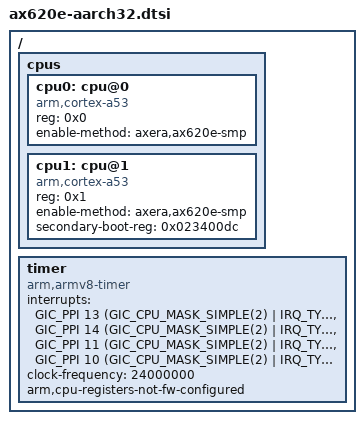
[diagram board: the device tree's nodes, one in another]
// SPDX-License-Identifier: GPL-2.0-or-later
/*
 * Copyright (c) 2026, GembaHive, Inc.
 */
/*
 * The AX620E's CPUs and timer under a 32-bit kernel. A board includes this
 * before its chip file, so these nodes come first in the DTB.
 */

#include <dt-bindings/interrupt-controller/arm-gic.h>

/ {
	cpus {
		#address-cells = <1>;
		#size-cells = <0>;

		cpu0: cpu@0 {
			device_type = "cpu";
			compatible = "arm,cortex-a53";
			reg = <0x0>;
			enable-method = "axera,ax620e-smp";
		};

		cpu1: cpu@1 {
			device_type = "cpu";
			compatible = "arm,cortex-a53";
			reg = <0x1>;
			enable-method = "axera,ax620e-smp";
			secondary-boot-reg = <0x023400dc>;
		};
	};

	/*
	 * A53 timer PPIs are active-low; no firmware sets CNTFRQ (the 24 MHz
	 * crystal) or CNTVOFF.
	 */
	timer {
		compatible = "arm,armv8-timer";
		interrupts = <GIC_PPI 13 (GIC_CPU_MASK_SIMPLE(2) | IRQ_TYPE_LEVEL_LOW)>,
			     <GIC_PPI 14 (GIC_CPU_MASK_SIMPLE(2) | IRQ_TYPE_LEVEL_LOW)>,
			     <GIC_PPI 11 (GIC_CPU_MASK_SIMPLE(2) | IRQ_TYPE_LEVEL_LOW)>,
			     <GIC_PPI 10 (GIC_CPU_MASK_SIMPLE(2) | IRQ_TYPE_LEVEL_LOW)>;
		clock-frequency = <24000000>;
		arm,cpu-registers-not-fw-configured;
	};
};
